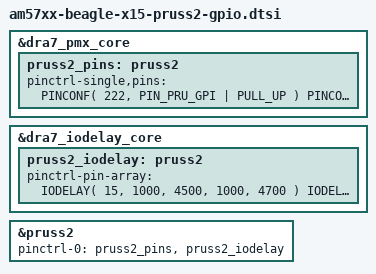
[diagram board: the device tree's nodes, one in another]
#include "dra7-pin-convenience.h"

// 122-142	pruss2 core 0 ioset 1 ( 0-20)
//
// 221-232	pruss2 core 0 ioset 2 ( 0-11)
// 201-204	pruss2 core 0 ioset 2 (12-15)
// 195-196	pruss2 core 0 ioset 2 (16-17)
// 189-190	pruss2 core 0 ioset 2 (18-19)
// 188-188	pruss2 core 0 ioset 2 (20-20)
//
// 143-159	pruss2 core 1 ioset 1 ( 0-16)
// 118-121	pruss2 core 1 ioset 1 (17-20)
//
// 208-212	pruss2 core 1 ioset 2 ( 0- 4)
// 165-166	pruss2 core 1 ioset 2 ( 5- 6)
// 169-169	pruss2 core 1 ioset 2 ( 7- 7)
// 173-174	pruss2 core 1 ioset 2 ( 8- 9)
// 181-187	pruss2 core 1 ioset 2 (10-16)
// 118-121	pruss2 core 1 ioset 2 (17-20)

&dra7_pmx_core {
	pruss2_pins: pruss2 {
		pinctrl-single,pins = <
			// pruss2 core 0 ioset 2
		//	PINCONF( 221, PIN_PRU_GPI )  // P17.05 io  0	
			PINCONF( 222, PIN_PRU_GPI | PULL_UP )  // P17.03 io  1	
			PINCONF( 223, PIN_PRU_GPI | PULL_UP )  // P17.34 io  2	
		//	PINCONF( 224, PIN_PRU_GPO )  // P17.04 io  3	
		//	PINCONF( 225, PIN_PRU_GPO )  // P17.07 io  4	
		//	PINCONF( 226, PIN_PRU_GPI )  // P17.36 io  5	
		//	PINCONF( 227, PIN_PRU_GPI )  // P17.08 io  6	
		//	PINCONF( 228, PIN_PRU_GPO )  // P17.33 io  7	
			PINCONF( 229, PIN_PRU_GPO )  // P17.37 io  8	
		//	PINCONF( 230, PIN_PRU_GPI )  // P17.35 io  9	
		//	PINCONF( 231, PIN_PRU_GPI )  // P17.38 io 10	
			PINCONF( 232, PIN_PRU_GPI | PULL_UP )  // P17.06 io 11	
		//	PINCONF( 195, PIN_PRU_GPI )  // P17.18 io 16	
		//	PINCONF( 196, PIN_PRU_GPI )  // P17.22 io 17	
		//	PINCONF( 189, PIN_PRU_GPI )  // P17.21 io 18	
		//	PINCONF( 190, PIN_PRU_GPI )  // P17.52 io 19	
		//	PINCONF( 188, PIN_PRU_GPI )  // P17.19 io 20	
		>;
	};
};

&dra7_iodelay_core {
	pruss2_iodelay: pruss2 {
		pinctrl-pin-array = <
			// pruss2 core 0 ioset 2
		//	IODELAY(  14, 1000, 3900, 1000, 4100 )  // P17.05  io  0
			IODELAY(  15, 1000, 4500, 1000, 4700 )  // P17.03  io  1
			IODELAY( 134, 1000, 4500, 1000, 4400 )  // P17.34  io  2
		//	IODELAY( 135, 1000, 4000, 1000, 4300 )  // P17.04  io  3
		//	IODELAY( 136, 1000, 4200, 1000, 3400 )  // P17.07  io  4
		//	IODELAY( 137, 1000, 3800, 1000, 3600 )  // P17.36  io  5
		//	IODELAY( 138, 1000, 3800, 1000, 3400 )  // P17.08  io  6
		//	IODELAY( 139, 1000, 4400, 1000, 3300 )  // P17.33  io  7
			IODELAY( 140, 1000, 4100, 1000, 4300 )  // P17.37  io  8
		//	IODELAY( 141, 1000, 4000, 1000, 4800 )  // P17.35  io  9
		//	IODELAY( 142, 1000, 3900, 1000, 3900 )  // P17.38  io 10
			IODELAY( 143, 1000, 3500, 1000, 4000 )  // P17.06  io 11
		//	IODELAY(  98,    0, 1700,    0, 1800 )  // P17.18  io 16
		//	IODELAY(  99,    0, 1800,    0, 1200 )  // P17.22  io 17
		//	IODELAY(  95,    0,  700,    0, 2600 )  // P17.21  io 18
		//	IODELAY( 105,    0, 1100,    0,    0 )  // P17.52  io 19
		//	IODELAY(  82,    0, 1800,    0, 1600 )  // P17.19  io 20
		>;
	};
};

&pruss2 {
	pinctrl-names = "default";
	pinctrl-0 = <&pruss2_pins>, <&pruss2_iodelay>;
};
